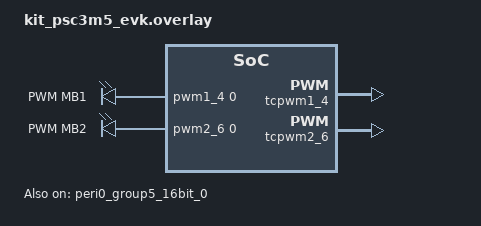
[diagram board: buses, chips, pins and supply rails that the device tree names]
/*
 * Copyright (c) 2026 Infineon Technologies AG,
 * or an affiliate of Infineon Technologies AG.
 *
 * SPDX-License-Identifier: Apache-2.0
 */

#include <zephyr/dt-bindings/pwm/pwm.h>
#include <zephyr/dt-bindings/pwm/pwm_ifx_tcpwm.h>

/*
 * The PSC3M5 only outputs some of the PWM devices to pins using the pin control driver.  None of
 * the PWM-Pin combinations available are tied to an LED on this board, so for this demonstration
 * we are using GPIO pins as the output of the PWM.  These can be connected to an external LED by
 * the user or observed on an oscilloscope.
 *
 * The PSC3 family allows any PWM output to be routed to any pin using the Trigger Mux functionality
 * of the part.  Once Zephyr support for the trigger mux configuration has been enabled this sample
 * will be updated to use the on-board LEDs.
 */

/ {
	aliases {
		pwm-led0 = &pwm_led0;
		pwm-led1 = &pwm_led1;
	};

	pwmleds {
		compatible = "pwm-leds";

		pwm_led0: pwm_led_0 {
			pwms = <&pwm1_4 0 PWM_MSEC(20) PWM_POLARITY_INVERTED>;
			label = "PWM MB1";
		};

		pwm_led1: pwm_led_1 {
			pwms = <&pwm2_6 0 PWM_MSEC(20) PWM_POLARITY_NORMAL>;
			label = "PWM MB2";
		};
	};
};

&tcpwm1_4 {
	status = "okay";

	pwm1_4: pwm1_4 {
		status = "okay";
		clocks = <&peri0_group5_16bit_0>;
		pinctrl-0 = <&p4_0_pwm1_4>;
		pinctrl-names = "default";
	};
};

&peri0_group5_16bit_0 {
	status = "okay";
	resource-type = <IFX_RSC_TCPWM>;
	resource-instance = <1>;
	resource-channel = <4>;
	clock-div = <9600>;
};

&tcpwm2_6 {
	status = "okay";

	pwm2_6: pwm2_6 {
		status = "okay";
		clocks = <&peri0_group5_16bit_0>;
		pinctrl-0 = <&p2_0_pwm2_6>;
		pinctrl-names = "default";
	};
};

&pinctrl {
	p4_0_pwm1_4: p4_0_pwm1_4 {
		drive-push-pull;
	};

	p2_0_pwm2_6: p2_0_pwm2_6 {
		drive-push-pull;
	};
};

&gpio_prt4 {
	status = "okay";
};

&gpio_prt2 {
	status = "okay";
};
